# liliumFP1_flpr register map
Vendor: Nordic Semiconductor; Series: liliumFP1; File version: 1
Registers are 32-bit, read-write, reset 0x0 unless marked. A register's access mark holds for its fields unless they carry their own. Offsets are from the block's base; [hi:lo] are bit positions; lines under a group give offsets from that group; {n}, {i} and the like mark numbered series.

## GLOBAL_STMDATA_NS — System Trace Macrocell data buffer 0
Base 0xA0000000
Same registers: GLOBAL_STMDATA_S 0xA0000000 (alternate view of GLOBAL_STMDATA_NS)
{0x0+0x2000000*i} DOMAIN[{i}] (i=0..15) group — Unspecified
  {0x0+j} NSDATA[{j}] (j=0..16777215) 8-bit — Description collection: NonSecure STM output data buffer for domain n. Writes to this region generates trace packets with id n+96.
  {0x1000000+j} SDATA[{j}] (j=0..16777215) 8-bit — Description collection: Secure STM output data buffer for domain n. Writes to this region generates trace packets with id n+32.
{0x0+0x1000000*i} BUFFER[{i}] (i=0..15) group (alternate view of DOMAIN[{i}]) — Raw buffer access to STM array. Use when DOMAIN array does not apply.
  {0x0+j} DATA[{j}] (j=0..16777215) 8-bit — Description collection: STM output data buffer n. Writes to this region generates trace packets.

## GLOBAL_TSGEN_NS — GENERIC
Base 0xBF041000
Same registers: GLOBAL_ETB_NS 0xBF044000, GLOBAL_ETR_NS 0xBF045000
0x00 TASKS_GENERICTASK wo — Generic event
  [0] TASKS_GENERICTASK
    1=Trigger task
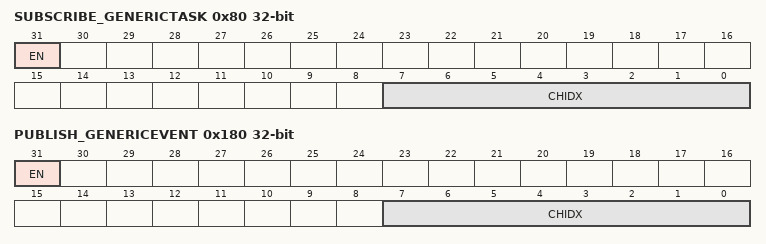
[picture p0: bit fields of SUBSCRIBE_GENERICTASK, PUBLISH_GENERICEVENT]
0x80 SUBSCRIBE_GENERICTASK — Subscribe configuration for task GENERICTASK
  [31] EN
    0=Disabled (Disable subscription); 1=Enabled (Enable subscription)
  [7:0] CHIDX — DPPI channel that task GENERICTASK will subscribe to
0x100 EVENTS_GENERICEVENT — Generic event
  [0] EVENTS_GENERICEVENT
    0=NotGenerated (Event not generated); 1=Generated (Event generated)
0x180 PUBLISH_GENERICEVENT — Publish configuration for event GENERICEVENT
  [31] EN
    0=Disabled (Disable publishing); 1=Enabled (Enable publishing)
  [7:0] CHIDX — DPPI channel that event GENERICEVENT will publish to
0x300 INTEN — Enable or disable interrupt
  [0] GENERICEVENT — Enable or disable interrupt for event GENERICEVENT
    0=Disabled; 1=Enabled
0x304 INTENSET — Enable interrupt
  [0] GENERICEVENT — Write '1' to enable interrupt for event GENERICEVENT
    on read: 0=Disabled (Read: Disabled); 1=Enabled (Read: Enabled) | on write: 1=Set (Enable)
0x308 INTENCLR — Disable interrupt
  [0] GENERICEVENT — Write '1' to disable interrupt for event GENERICEVENT
    on read: 0=Disabled (Read: Disabled); 1=Enabled (Read: Enabled) | on write: 1=Clear (Disable)

## VPRCLIC_NS — VPR CLIC registers 0
Base 0x4F8D4000
Same registers: VPRCLIC_S 0x5F8D4000
0x1000 CLIC group — Unspecified
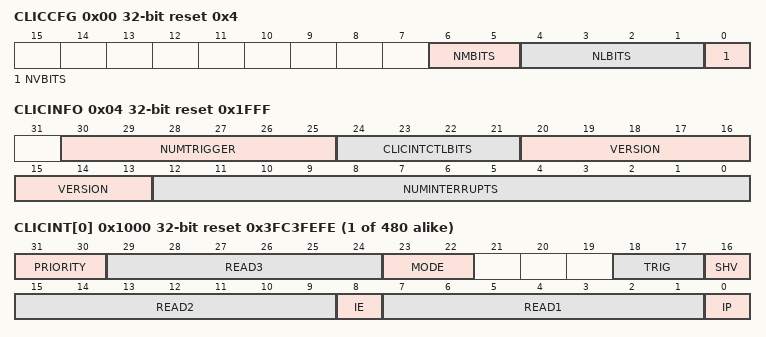
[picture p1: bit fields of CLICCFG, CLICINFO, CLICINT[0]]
  0x00 CLICCFG ro reset 0x4 — CLIC configuration.
    [6:5] NMBITS — Interrupt privilege mode.
      0=ModeM (All interrupts are M-mode only); 1=ModeS (Interrupts can be S-mode); 2=ModeSU (Interrupts can be S-mode or U-mode)
    [4:1] NLBITS — Interrupt level encoding.
    [0] NVBITS — Selective interrupt hardware vectoring.
      0=NotImplemented (Selective interrupt hardware vectoring is not implemented); 1=Implemented (Selective interrupt hardware vectoring is implemented)
  0x04 CLICINFO ro reset 0x1FFF — CLIC information.
    [30:25] NUMTRIGGER — Number of maximum interrupt triggers supported
    [24:21] CLICINTCTLBITS — Implemented bit in the CLICINT.CTL register.
    [20:13] VERSION
    [12:0] NUMINTERRUPTS — Maximum number of interrupts supported.
  {0x1000+4j} CLICINT[{j}] (j=0..479) reset 0x3FC3FEFE — Description collection: Interrupt control register for IRQ number [n].
    [31:30] PRIORITY — Interrupt priority.
    [29:24] READ3 ro — Read as 1, write ignored.
    [23:22] MODE ro — Privilege mode.
      0=UserMode; 1=SupervisorMode; 3=MachineMode
    [18:17] TRIG ro — Trigger type and polarity for each interrupt input.
      0=LevelTriggered (Interrupts are level-triggered); 1=EdgeTriggered (Interrupts are edge-triggered); 2=NegativeLevel (Interrupts are negative level-triggered); 3=NegativeEdge (Interrupts are negative edge-triggered)
    [16] SHV ro — Selective Hardware Vectoring.
      0=NonVectored (Interrupt to be non-vectored); 1=Vectored (Hardware vectored)
    [15:9] READ2 ro — Read as 1, write ignored.
    [8] IE — Interrupt enable bit.
      0=Disabled (Interrupt disabled); 1=Enabled (Interrupt enabled)
    [7:1] READ1 ro — Read as 1, write ignored.
    [0] IP — Interrupt Pending bit.
      0=NotPending (Interrupt not pending); 1=Pending (Interrupt pending)

## Notices in the file
Copyright (c) 2010 - 2022, Nordic Semiconductor ASA
All rights reserved.
Redistribution and use in source and binary forms, with or without modification,
are permitted provided that the following conditions are met:
1. Redistributions of source code must retain the above copyright notice, this
list of conditions and the following disclaimer.
2. Redistributions in binary form, except as embedded into a Nordic
Semiconductor ASA integrated circuit in a product or a software update for
such product, must reproduce the above copyright notice, this list of
conditions and the following disclaimer in the documentation and/or other
materials provided with the distribution.
3. Neither the name of Nordic Semiconductor ASA nor the names of its
contributors may be used to endorse or promote products derived from this
software without specific prior written permission.
4. This software, with or without modification, must only be used with a
Nordic Semiconductor ASA integrated circuit.
5. Any software provided in binary form under this license must not be reverse
engineered, decompiled, modified and/or disassembled.
THIS SOFTWARE IS PROVIDED BY NORDIC SEMICONDUCTOR ASA "AS IS" AND ANY EXPRESS
OR IMPLIED WARRANTIES, INCLUDING, BUT NOT LIMITED TO, THE IMPLIED WARRANTIES
OF MERCHANTABILITY, NONINFRINGEMENT, AND FITNESS FOR A PARTICULAR PURPOSE ARE
DISCLAIMED. IN NO EVENT SHALL NORDIC SEMICONDUCTOR ASA OR CONTRIBUTORS BE
LIABLE FOR ANY DIRECT, INDIRECT, INCIDENTAL, SPECIAL, EXEMPLARY, OR
CONSEQUENTIAL DAMAGES (INCLUDING, BUT NOT LIMITED TO, PROCUREMENT OF SUBSTITUTE
GOODS OR SERVICES; LOSS OF USE, DATA, OR PROFITS; OR BUSINESS INTERRUPTION)
HOWEVER CAUSED AND ON ANY THEORY OF LIABILITY, WHETHER IN CONTRACT, STRICT
LIABILITY, OR TORT (INCLUDING NEGLIGENCE OR OTHERWISE) ARISING IN ANY WAY OUT
OF THE USE OF THIS SOFTWARE, EVEN IF ADVISED OF THE POSSIBILITY OF SUCH DAMAGE.
